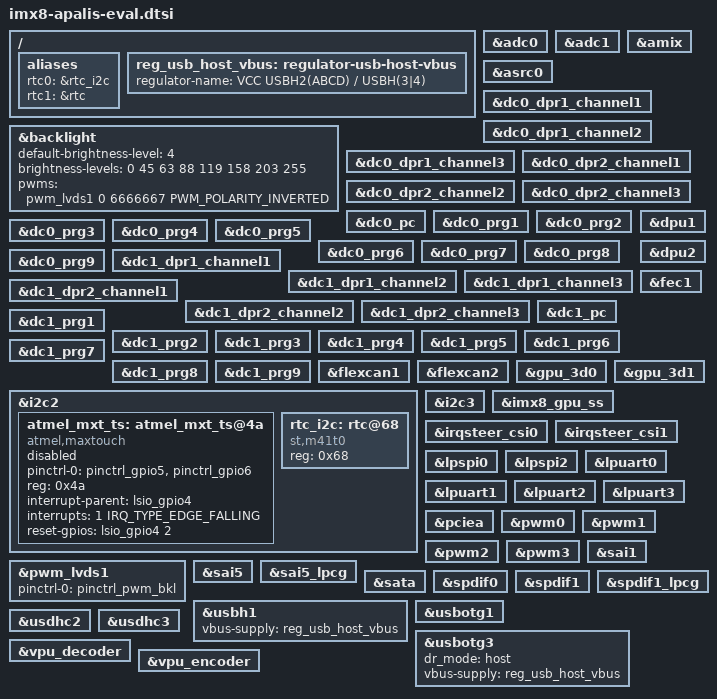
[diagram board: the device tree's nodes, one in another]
// SPDX-License-Identifier: GPL-2.0+ OR X11
/*
 * Copyright 2019-2020 Toradex
 */

#include <dt-bindings/pwm/pwm.h>

/ {
	aliases {
		rtc0 = &rtc_i2c;
		rtc1 = &rtc;
	};

	reg_usb_host_vbus: regulator-usb-host-vbus {
		regulator-name = "VCC USBH2(ABCD) / USBH(3|4)";
	};
};

&adc0 {
	status = "okay";
};

&adc1 {
	status = "okay";
};

&amix {
	status = "okay";
};

&asrc0 {
	status = "okay";
};

&backlight {
	default-brightness-level = <4>;
	brightness-levels = <0 45 63 88 119 158 203 255>;
	pwms = <&pwm_lvds1 0 6666667 PWM_POLARITY_INVERTED>;
	status = "okay";
};

&dc0_dpr1_channel1 {
	status = "okay";
};

&dc0_dpr1_channel2 {
	status = "okay";
};

&dc0_dpr1_channel3 {
	status = "okay";
};

&dc0_dpr2_channel1 {
	status = "okay";
};

&dc0_dpr2_channel2 {
	status = "okay";
};

&dc0_dpr2_channel3 {
	status = "okay";
};

&dc0_pc {
	status = "okay";
};

&dc0_prg1 {
	status = "okay";
};

&dc0_prg2 {
	status = "okay";
};

&dc0_prg3 {
	status = "okay";
};

&dc0_prg4 {
	status = "okay";
};

&dc0_prg5 {
	status = "okay";
};

&dc0_prg6 {
	status = "okay";
};

&dc0_prg7 {
	status = "okay";
};

&dc0_prg8 {
	status = "okay";
};

&dc0_prg9 {
	status = "okay";
};

&dc1_dpr1_channel1 {
	status = "okay";
};

&dc1_dpr1_channel2 {
	status = "okay";
};

&dc1_dpr1_channel3 {
	status = "okay";
};

&dc1_dpr2_channel1 {
	status = "okay";
};

&dc1_dpr2_channel2 {
	status = "okay";
};

&dc1_dpr2_channel3 {
	status = "okay";
};

&dc1_pc {
	status = "okay";
};

&dc1_prg1 {
	status = "okay";
};

&dc1_prg2 {
	status = "okay";
};

&dc1_prg3 {
	status = "okay";
};

&dc1_prg4 {
	status = "okay";
};

&dc1_prg5 {
	status = "okay";
};

&dc1_prg6 {
	status = "okay";
};

&dc1_prg7 {
	status = "okay";
};

&dc1_prg8 {
	status = "okay";
};

&dc1_prg9 {
	status = "okay";
};

&dpu1 {
	status = "okay";
};

&dpu2 {
	status = "okay";
};

&fec1 {
	status = "okay";
};

&flexcan1 {
	status = "okay";
};

&flexcan2 {
	status = "okay";
};

&gpu_3d0{
	status = "okay";
};

&gpu_3d1{
	status = "okay";
};

/* Apalis I2C1 */
&i2c2 {
	status = "okay";

	atmel_mxt_ts: atmel_mxt_ts@4a {
		compatible = "atmel,maxtouch";
		pinctrl-names = "default";
		pinctrl-0 = <&pinctrl_gpio5>, <&pinctrl_gpio6>;
		reg = <0x4a>;
		interrupt-parent = <&lsio_gpio4>;
		interrupts = <1 IRQ_TYPE_EDGE_FALLING>;    /* Apalis GPIO5 */
		reset-gpios = <&lsio_gpio4 2 GPIO_ACTIVE_HIGH>; /* Apalis GPIO6 */
		status = "disabled";
	};

	/* M41T0M6 real time clock on carrier board */
	rtc_i2c: rtc@68 {
		compatible = "st,m41t0";
		reg = <0x68>;
	};
};

/* Apalis I2C3 (CAM) */
&i2c3 {
	status = "okay";
};

&imx8_gpu_ss {
	status = "okay";
};

&irqsteer_csi0 {
	status = "okay";
};

&irqsteer_csi1 {
	status = "okay";
};

/* Apalis SPI1 */
&lpspi0 {
	status = "okay";
};

/* Apalis SPI2 */
&lpspi2 {
	status = "okay";
};

/* Apalis UART3 */
&lpuart0 {
	status = "okay";
};

/* Apalis UART1 */
&lpuart1 {
	status = "okay";
};

/* Apalis UART4 */
&lpuart2 {
	status = "okay";
};

/* Apalis UART2 */
&lpuart3 {
	status = "okay";
};

/* Apalis PCIE1 */
&pciea{
	status = "okay";
};

/* Apalis PWM3, MXM3 pin 6 */
&pwm0 {
	status = "okay";
};

/* Apalis PWM4, MXM3 pin 8 */
&pwm1 {
	status = "okay";
};

/* Apalis PWM1, MXM3 pin 2 */
&pwm2 {
	status = "okay";
};

/* Apalis PWM2, MXM3 pin 4 */
&pwm3 {
	status = "okay";
};

&pwm_lvds1 {
	pinctrl-names = "default";
	pinctrl-0 = <&pinctrl_pwm_bkl>;
	status = "okay";
};

&sai1 {
	status = "okay";
};

&sai5 {
	status = "okay";
};

&sai5_lpcg {
	status = "okay";
};

/* Apalis SATA1 */
&sata {
	status = "okay";
};

/* Apalis SPDIF1 */
&spdif0 {
	status = "okay";
};

&spdif1 {
	status = "okay";
};

&spdif1_lpcg {
	status = "okay";
};

/* Apalis USBH2, Apalis USBH3 and on-module Wi-Fi via on-module HSIC Hub */
&usbh1 {
	vbus-supply = <&reg_usb_host_vbus>;
	status = "okay";
};

/* Apalis USBO1 */
&usbotg1 {
	status = "okay";
};

/* Apalis USBH4 SuperSpeed */
&usbotg3 {
	dr_mode = "host";
	vbus-supply = <&reg_usb_host_vbus>;
	status = "okay";
};

/* Apalis MMC1 */
&usdhc2 {
	status = "okay";
};

/* Apalis SD1 */
&usdhc3 {
	status = "okay";
};

&vpu_decoder {
	status = "okay";
};

&vpu_encoder {
	status = "okay";
};

